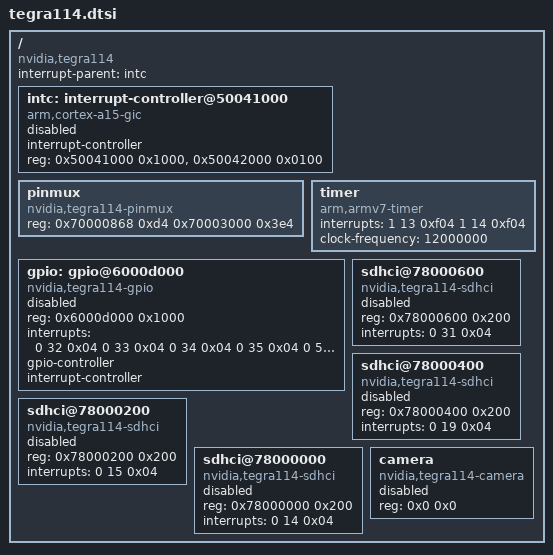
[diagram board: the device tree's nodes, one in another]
/*
 * Copyright (c) 2012-2013, NVIDIA CORPORATION.  All rights reserved.
 *
 * This program is free software; you can redistribute it and/or modify
 * it under the terms of the GNU General Public License version 2 as
 * published by the Free Software Foundation.
 *
 */

/include/ "skeleton.dtsi"

/ {
	compatible = "nvidia,tegra114";
	interrupt-parent = <&intc>;

	intc: interrupt-controller@50041000 {
		compatible = "arm,cortex-a15-gic";
		interrupt-controller;
		#interrupt-cells = <3>;
		reg = <0x50041000 0x1000>,
		      <0x50042000 0x0100>;
		status = "disabled";
	};

	pinmux: pinmux {
		compatible = "nvidia,tegra114-pinmux";
		reg = <0x70000868 0xd4    /* Pad control registers */
		       0x70003000 0x3e4>; /* Mux registers */
	};

	timer {
		compatible = "arm,armv7-timer";
		interrupts = <1 13 0xf04
			      1 14 0xf04>;
		clock-frequency = <12000000>;
	};

	gpio: gpio@6000d000 {
		compatible = "nvidia,tegra114-gpio", "nvidia,tegra30-gpio";
		reg = <0x6000d000 0x1000>;
		interrupts = <0 32 0x04
				0 33 0x04
				0 34 0x04
				0 35 0x04
				0 55 0x04
				0 87 0x04
				0 89 0x04
				0 125 0x04>;
		#gpio-cells = <2>;
		gpio-controller;
		#interrupt-cells = <2>;
		interrupt-controller;
		status = "disable";
	};

	sdhci@78000600 {
		compatible = "nvidia,tegra114-sdhci", "nvidia,tegra20-sdhci";
		reg = <0x78000600 0x200>;
		interrupts = < 0 31 0x04 >;
		status = "disable";
	};
	sdhci@78000400 {
		compatible = "nvidia,tegra114-sdhci", "nvidia,tegra20-sdhci";
		reg = <0x78000400 0x200>;
		interrupts = < 0 19 0x04 >;
		status = "disable";
	};
	sdhci@78000200 {
		compatible = "nvidia,tegra114-sdhci", "nvidia,tegra20-sdhci";
		reg = <0x78000200 0x200>;
		interrupts = < 0 15 0x04 >;
		status = "disable";
	};
	sdhci@78000000 {
		compatible = "nvidia,tegra114-sdhci", "nvidia,tegra20-sdhci";
		reg = <0x78000000 0x200>;
		interrupts = < 0 14 0x04 >;
		status = "disable";
	};

	camera {
		compatible = "nvidia,tegra114-camera", "nvidia,tegra20-camera";
		reg = <0x0 0x0>;
		status = "disable";
	};
};
